# I2S register map
Vendor: Texas Instruments
Peripheral module from a debugger description file (folder CC2650).
Registers are 32-bit, access per field, reset 0x0 unless marked. A register's access mark holds for its fields unless they carry their own. Offsets are as the file gives them; lines under a group give offsets from that group; [hi:lo] are bit positions; {n}, {i} and the like mark numbered series; 'fields as' and 'values as' point back to an identical list; <NAME> marks a mode.

## I2S — I2S Audio DMA module supporting formats I2S, LJF, RJF and DSP
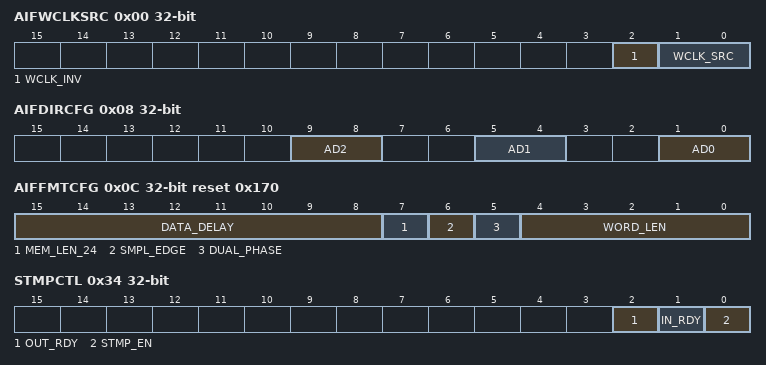
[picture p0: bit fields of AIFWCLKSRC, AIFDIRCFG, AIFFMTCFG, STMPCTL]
0x00 AIFWCLKSRC — WCLK Source Selection
  [2] WCLK_INV rw — Inverts WCLK source (pad or internal) when set. 0: Not inverted 1: Inverted
  [1:0] WCLK_SRC rw — Selects WCLK source for AIF (should be the same as the BCLK source). The BCLK source is defined in the PRCM:I2SBCLKSEL.SRC
    3=RESERVED (Not supported. Will give same WCLK as 'NONE' ('00')); 2=INT (Internal WCLK generator, from module PRCM/ClkCtrl); 1=EXT (External WCLK generator, from pad); 0=NONE (None ('0'))
0x04 AIFDMACFG — DMA Buffer Size Configuration
  [7:0] END_FRAME_IDX rw — Defines the length of the Writing a non-zero value to this registerfield enables and initializes AIF. Note that before doing so, all other configuration must have been done, and AIFINPTR/AIFOUTPTR must have been loaded.
0x08 AIFDIRCFG — Pin Direction
  [all] fields
    2=OUT (Output mode); 1=IN (Input mode); 0=DIS (Not in use (disabled))
  [9:8] AD2 rw — Configures the AD2 audio data pin usage 0x3: Reserved
  [5:4] AD1 rw — Configures the AD1 audio data pin usage: 0x3: Reserved
  [1:0] AD0 rw — Configures the AD0 audio data pin usage: 0x3: Reserved
0x0C AIFFMTCFG reset 0x170 — Serial Interface Format Configuration
  [15:8] DATA_DELAY rw — The number of BCLK periods between a WCLK edge and MSB of the first word in a phase: 0x00: LJF format 0x01: I2S and DSP format 0x02: RJF format ... 0xFF: RJF format Note: When 0, MSB of the next word will be output in the idle period between LSB of the previous word and the start of the next word. Otherwise logical 0 will be output until the data delay has expired.
  [7] MEM_LEN_24 rw — The size of each word stored to or loaded from memory:
    1=24BIT (24-bit (one 8 bit and one 16 bit locked access per sample)); 0=16BIT (16-bit (one 16 bit access per sample))
  [6] SMPL_EDGE rw — On the serial audio interface, data (and wclk) is sampled and clocked out on opposite edges of BCLK.
    1=POS (Data is sampled on the positive edge and clocked out on the negative edge.); 0=NEG (Data is sampled on the negative edge and clocked out on the positive edge.)
  [5] DUAL_PHASE rw — Selects dual- or single-phase format. 0: Single-phase 1: Dual-phase
  [4:0] WORD_LEN rw — Number of bits per word (8-24): In single-phase format, this is the exact number of bits per word. In dual-phase format, this is the maximum number of bits per word. Values below 8 and above 24 give undefined behavior. Data written to memory is always aligned to 16 or 24 bits as defined by MEM_LEN_24. Bit widths that differ from this alignment will either be truncated or zero padded.
0x10 AIFWMASK0 rw reset 0x3 — Word Selection Bit Mask for Pin 0
  [7:0] MASK — Bit-mask indicating valid channels in a frame on AD0. In single-phase mode, each bit represents one channel, starting with LSB for the first word in the frame. A frame can contain up to 8 channels. Channels that are not included in the mask will not be sampled and stored in memory, and clocked out as '0'. In dual-phase mode, only the two LSBs are considered. For a stereo configuration, set both bits. For a mono configuration, set bit 0 only. In mono mode, only channel 0 will be sampled and stored to memory, and channel 0 will be repeated when clocked out. In mono mode, only channel 0 will be sampled and stored to memory, and channel 0 will be repeated in the second phase when clocked out. If all bits are zero, no input words will be stored to memory, and the output data lines will be constant '0'. This can be utilized when PWM debug output is desired without any actively used output pins.
0x14 AIFWMASK1 reset 0x3 — Word Selection Bit Mask for Pin 1
  [7:0] MASK rw — Bit-mask indicating valid channels in a frame on AD1. In single-phase mode, each bit represents one channel, starting with LSB for the first word in the frame. A frame can contain up to 8 channels. Channels that are not included in the mask will not be sampled and stored in memory, and clocked out as '0'. In dual-phase mode, only the two LSBs are considered. For a stereo configuration, set both bits. For a mono configuration, set bit 0 only. In mono mode, only channel 0 will be sampled and stored to memory, and channel 0 will be repeated when clocked out. In mono mode, only channel 0 will be sampled and stored to memory, and channel 0 will be repeated in the second phase when clocked out. If all bits are zero, no input words will be stored to memory, and the output data lines will be constant '0'. This can be utilized when PWM debug output is desired without any actively used output pins.
0x18 AIFWMASK2 reset 0x3 — Word Selection Bit Mask for Pin 2
  [7:0] MASK rw — Bit-mask indicating valid channels in a frame on AD2 In single-phase mode, each bit represents one channel, starting with LSB for the first word in the frame. A frame can contain up to 8 channels. Channels that are not included in the mask will not be sampled and stored in memory, and clocked out as '0'. In dual-phase mode, only the two LSBs are considered. For a stereo configuration, set both bits. For a mono configuration, set bit 0 only. In mono mode, only channel 0 will be sampled and stored to memory, and channel 0 will be repeated when clocked out. In mono mode, only channel 0 will be sampled and stored to memory, and channel 0 will be repeated in the second phase when clocked out. If all bits are zero, no input words will be stored to memory, and the output data lines will be constant '0'. This can be utilized when PWM debug output is desired without any actively used output pins.
0x1C AIFPWMVALUE — Audio Interface PWM Debug Value
  [15:0] PULSE_WIDTH rw — The value written to this register determines the width of the active high PWM pulse (pwm_debug), which starts together with MSB of the first output word in a DMA buffer: 0x0000: Constant low 0x0001: Width of the pulse (number of BCLK cycles, here 1). ... 0xFFFE: Width of the pulse (number of BCLK cycles, here 65534). 0xFFFF: Constant high
0x20 AIFINPTRNEXT rw — DMA Input Buffer Next Pointer
  [31:0] PTR — Pointer to the first byte in the next DMA input buffer. The read value equals the last written value until the currently used DMA input buffer is completed, and then becomes null when the last written value is transferred to the DMA controller to start on the next buffer. This event is signalized by aif_dma_in_irq. At startup, the value should be written once before and once after configuring the DMA buffer size in AIFDMACFG. The next pointer must be written to this register while the DMA function uses the previously written pointer. If not written in time, IRQFLAGS.PTR_ERR will be raised and all input pins will be disabled. Note the following limitations: - Address space wrapping is not supported (i.e. address(last sample) must be higher than address(first sample). - A DMA block cannot be aligned with the end of the address space (i.e. a block cannot contain the address 0xFFFF)
0x24 AIFINPTR rw — DMA Input Buffer Current Pointer
  [31:0] PTR — Value of the DMA input buffer pointer currently used by the DMA controller. Incremented by 1 (byte) or 2 (word) for each AHB access.
0x28 AIFOUTPTRNEXT rw — DMA Output Buffer Next Pointer
  [31:0] PTR — Pointer to the first byte in the next DMA output buffer. The read value equals the last written value until the currently used DMA output buffer is completed, and then becomes null when the last written value is transferred to the DMA controller to start on the next buffer. This event is signalized by aif_dma_out_irq. At startup, the value should be written once before and once after configuring the DMA buffer size in AIFDMACFG. At this time, the first two samples will be fetched from memory. The next pointer must be written to this register while the DMA function uses the previously written pointer. If not written in time, IRQFLAGS.PTR_ERR will be raised and all output pins will be disabled. Note the following limitations: - Address space wrapping is not supported (i.e. address(last sample) must be higher than address(first sample). - A DMA block cannot be aligned with the end of the address space (i.e. a block cannot contain the address 0xFFFF)
0x2C AIFOUTPTR rw — DMA Output Buffer Current Pointer
  [31:0] PTR — Value of the DMA output buffer pointer currently used by the DMA controller Incremented by 1 (byte) or 2 (word) for each AHB access.
0x34 STMPCTL — SampleStaMP Generator Control Register
  [2] OUT_RDY ro — Low until the output pins are ready to be started by the samplestamp generator. When started (i.e. STMPOUTTRIG equals the WCLK counter) the bit goes back low.
  [1] IN_RDY ro — Low until the input pins are ready to be started by the samplestamp generator. When started (i.e. STMPINTRIG equals the WCLK counter) the bit goes back low.
  [0] STMP_EN rw — Enables the samplestamp generator. The samplestamp generator should only be enabled after it has been properly configured. When cleared, all samplestamp generator counters and capture values are cleared.
0x38 STMPXCNTCAPT0 ro — Captured XOSC Counter Value, Capture Channel 0
  [15:0] CAPT_VALUE — The value of the samplestamp XOSC counter (STMPXCNT.CURR_VALUE) last time an event was pulsed (event source selected in [EVENT.I2SSTMPSEL0.EV] for channel 0). This number corresponds to the number of 24 MHz clock cycles since the last positive edge of the selected WCLK. The value is cleared when STMPCTL.STMP_EN = 0. Note: Due to buffering and synchronization, WCLK is delayed by a small number of BCLK periods and clk periods. Note: When calculating the fractional part of the sample stamp, STMPXPER may be less than this bit field.
0x3C STMPXPER ro — XOSC Period Value
  [15:0] VALUE — The number of 24 MHz clock cycles in the previous WCLK period (i.e. the next value of the XOSC counter at the positive WCLK edge, had it not been reset to 0). The value is cleared when STMPCTL.STMP_EN = 0.
0x40 STMPWCNTCAPT0 ro — Captured WCLK Counter Value, Capture Channel 0
  [15:0] CAPT_VALUE — The value of the samplestamp WCLK counter (STMPWCNT.CURR_VALUE) last time an event was pulsed (event source selected in EVENT:I2SSTMPSEL0.EV for channel 0). This number corresponds to the number of positive WCLK edges since the samplestamp generator was enabled (not taking modification through STMPWADD/STMPWSET into account). The value is cleared when STMPCTL.STMP_EN = 0.
0x44 STMPWPER — WCLK Counter Period Value
  [15:0] VALUE rw — Used to define when STMPWCNT is to be reset so number of WCLK edges are found for the size of the sample buffer. This is thus a modulo value for the WCLK counter. This number should correspond to the size of the sample buffer used by the system (i.e. the index of the last sample plus 1).
0x48 STMPINTRIG — WCLK Counter Trigger Value for Input Pins
  [15:0] IN_START_WCNT rw — Compare value used to start the incoming audio streams. This bit field shall equal the WCLK counter value during the WCLK period in which the first input word(s) are sampled and stored to memory (i.e. the sample at the start of the very first DMA input buffer). The value of this register takes effect when the following conditions are met: - One or more pins are configured as inputs in AIFDIRCFG. - AIFDMACFG has been configured for the correct buffer size, and at least 32 BCLK cycle ticks have happened. Note: To avoid false triggers, this bit field should be set higher than STMPWPER.VALUE.
0x4C STMPOUTTRIG — WCLK Counter Trigger Value for Output Pins
  [15:0] OUT_START_WCNT rw — Compare value used to start the outgoing audio streams. This bit field shall equal the WCLK counter value during the WCLK period in which the first output word(s) read from memory are clocked out (i.e. the sample at the start of the very first DMA output buffer). The value of this register takes effect when the following conditions are met: - One or more pins are configured as outputs in AIFDIRCFG. - AIFDMACFG has been configured for the correct buffer size, and 32 BCLK cycle ticks have happened. - 2 samples have been preloaded from memory (examine the AIFOUTPTR register if necessary). Note: The memory read access is only performed when required, i.e. channels 0/1 must be selected in AIFWMASK0/AIFWMASK1. Note: To avoid false triggers, this bit field should be set higher than STMPWPER.VALUE.
0x50 STMPWSET — WCLK Counter Set Operation
  [15:0] VALUE rw — WCLK counter modification: Sets the running WCLK counter equal to the written value.
0x54 STMPWADD — WCLK Counter Add Operation
  [15:0] VALUE_INC rw — WCLK counter modification: Adds the written value to the running WCLK counter. If a positive edge of WCLK occurs at the same time as the operation, this will be taken into account. This operation is typically used to adjust the WCLK counter after receiving the first WASP beacon. To add a negative value, write "STMPWPER.VALUE - value".
0x58 STMPXPERMIN reset 0xFFFF — XOSC Minimum Period Value Minimum Value of STMPXPER
  [15:0] VALUE rw — Each time STMPXPER is updated, the value is also loaded into this register, provided that the value is smaller than the current value in this register. When written, the register is reset to 0xFFFF (65535), regardless of the value written. The minimum value can be used to detect extra WCLK pulses (this registers value will be significantly smaller than STMPXPER.VALUE).
0x5C STMPWCNT ro — Current Value of WCNT
  [15:0] CURR_VALUE — Current value of the WCLK counter
0x60 STMPXCNT ro — Current Value of XCNT
  [15:0] CURR_VALUE — Current value of the XOSC counter, latched when reading STMPWCNT.
0x64 STMPXCNTCAPT1 ro — Captured XOSC Counter Value, Capture Channel 1
  [15:0] CAPT_VALUE — Channel 1 is idle and can not be sampled from an external pulse as with Channel 0 STMPXCNTCAPT0
0x68 STMPWCNTCAPT1 ro — Captured WCLK Counter Value, Capture Channel 1
  [15:0] CAPT_VALUE — Channel 1 is idle and can not be sampled from an external event as with Channel 0 STMPWCNTCAPT0
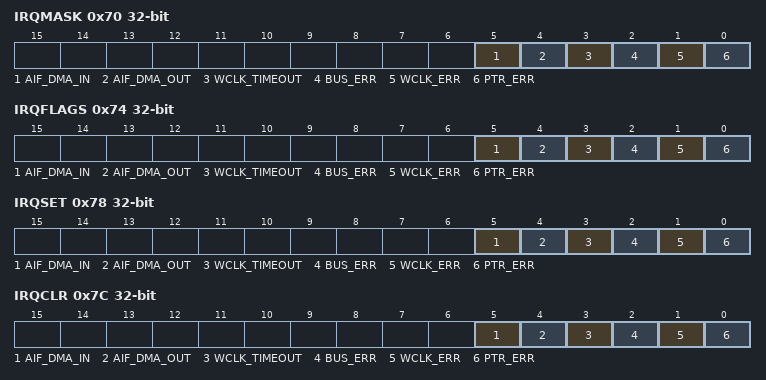
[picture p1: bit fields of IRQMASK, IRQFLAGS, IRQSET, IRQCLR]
0x70 IRQMASK rw — Masked Interrupt Status Register
  [5] AIF_DMA_IN — Defines the masks state for the interrupt of IRQFLAGS.AIF_DMA_IN 0: Disable 1: Enable
  [4] AIF_DMA_OUT — Defines the masks state for the interrupt of IRQFLAGS.AIF_DMA_OUT 0: Disable 1: Enable
  [3] WCLK_TIMEOUT — Defines the masks state for the interrupt of IRQFLAGS.WCLK_TIMEOUT 0: Disable 1: Enable
  [2] BUS_ERR — Defines the masks state for the interrupt of IRQFLAGS.BUS_ERR 0: Disable 1: Enable
  [1] WCLK_ERR — Defines the masks state for the interrupt of IRQFLAGS.WCLK_ERR 0: Disable 1: Enable
  [0] PTR_ERR — Defines the masks state for the interrupt of IRQFLAGS.PTR_ERR 0: Disable 1: Enable
0x74 IRQFLAGS ro — Raw Interrupt Status Register
  [5] AIF_DMA_IN — Set when condition for this bit field event occurs (auto cleared when input pointer is updated - AIFINPTR), see description of AIFINPTR register
  [4] AIF_DMA_OUT — Set when condition for this bit field event occurs (auto cleared when output pointer is updated - AIFOUTPTR), see description of AIFOUTPTR register for details
  [3] WCLK_TIMEOUT — Set when the sample stamp generator does not detect a positive WCLK edge for 65535 clk periods. This signalizes that the internal or external BCLK and WCLK generator source has been disabled. The bit is sticky and may only be cleared by software (by writing '1' to IRQCLR.WCLK_TIMEOUT).
  [2] BUS_ERR — Set when a DMA operation is not completed in time (i.e. audio output buffer underflow, or audio input buffer overflow). This error requires a complete restart since word synchronization has been lost. The bit is sticky and may only be cleared by software (by writing '1' to IRQCLR.BUS_ERR). Note that DMA initiated transactions to illegal addresses will not trigger an interrupt. The response to such transactions is undefined.
  [1] WCLK_ERR — Set when: - An unexpected WCLK edge occurs during the data delay period of a phase. Note unexpected WCLK edges during the word and idle periods of the phase are not detected. - In dual-phase mode, when two WCLK edges are less than 4 BCLK cycles apart. - In single-phase mode, when a WCLK pulse occurs before the last channel. This error requires a complete restart since word synchronization has been lost. The bit is sticky and may only be cleared by software (by writing '1' to IRQCLR.WCLK_ERR).
  [0] PTR_ERR — Set when AIFINPTRNEXT or AIFOUTPTRNEXT has not been loaded with the next block address in time. This error requires a complete restart since word synchronization has been lost. The bit is sticky and may only be cleared by software (by writing '1' to IRQCLR.PTR_ERR).
0x78 IRQSET wo — Interrupt Set Register
  [5] AIF_DMA_IN — 1: Sets the interrupt of IRQFLAGS.AIF_DMA_IN (unless a auto clear criteria was given at the same time, in which the set will be ignored)
  [4] AIF_DMA_OUT — 1: Sets the interrupt of IRQFLAGS.AIF_DMA_OUT (unless a auto clear criteria was given at the same time, in which the set will be ignored)
  [3] WCLK_TIMEOUT — 1: Sets the interrupt of IRQFLAGS.WCLK_TIMEOUT
  [2] BUS_ERR — 1: Sets the interrupt of IRQFLAGS.BUS_ERR
  [1] WCLK_ERR — 1: Sets the interrupt of IRQFLAGS.WCLK_ERR
  [0] PTR_ERR — 1: Sets the interrupt of IRQFLAGS.PTR_ERR
0x7C IRQCLR wo — Interrupt Clear Register
  [5] AIF_DMA_IN — 1: Clears the interrupt of IRQFLAGS.AIF_DMA_IN (unless a set criteria was given at the same time in which the clear will be ignored)
  [4] AIF_DMA_OUT — 1: Clears the interrupt of IRQFLAGS.AIF_DMA_OUT (unless a set criteria was given at the same time in which the clear will be ignored)
  [3] WCLK_TIMEOUT — 1: Clears the interrupt of IRQFLAGS.WCLK_TIMEOUT (unless a set criteria was given at the same time in which the clear will be ignored)
  [2] BUS_ERR — 1: Clears the interrupt of IRQFLAGS.BUS_ERR (unless a set criteria was given at the same time in which the clear will be ignored)
  [1] WCLK_ERR — 1: Clears the interrupt of IRQFLAGS.WCLK_ERR (unless a set criteria was given at the same time in which the clear will be ignored)
  [0] PTR_ERR — 1: Clears the interrupt of IRQFLAGS.PTR_ERR (unless a set criteria was given at the same time in which the clear will be ignored)
